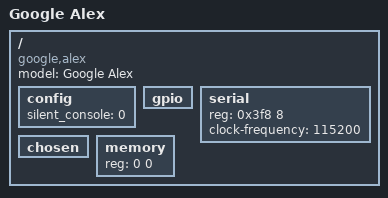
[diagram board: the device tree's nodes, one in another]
/dts-v1/;

/include/ "coreboot.dtsi"

/ {
	#address-cells = <1>;
	#size-cells = <1>;
	model = "Google Alex";
	compatible = "google,alex", "intel,atom-pineview";

	config {
	       silent_console = <0>;
	};

	gpio: gpio {};

	serial {
		reg = <0x3f8 8>;
		clock-frequency = <115200>;
	};

	chosen { };
	memory { device_type = "memory"; reg = <0 0>; };
};
